# MIMXRT1011 register map
Vendor: nxp.com; File version: 1.0
CPU: CM7 r0p1, little endian, MPU, FPU, VTOR, 4 interrupt priority bits
Registers are 32-bit, read-write, reset 0x0 unless marked. A register's access mark holds for its fields unless they carry their own. Offsets are from the block's base; [hi:lo] are bit positions; 'fields as' and 'values as' point back to an identical list.

## TEMPMON — Temperature Monitor
Base 0x400D8000; register names take the prefix TEMPMON_; alternate view of CCM_ANALOG
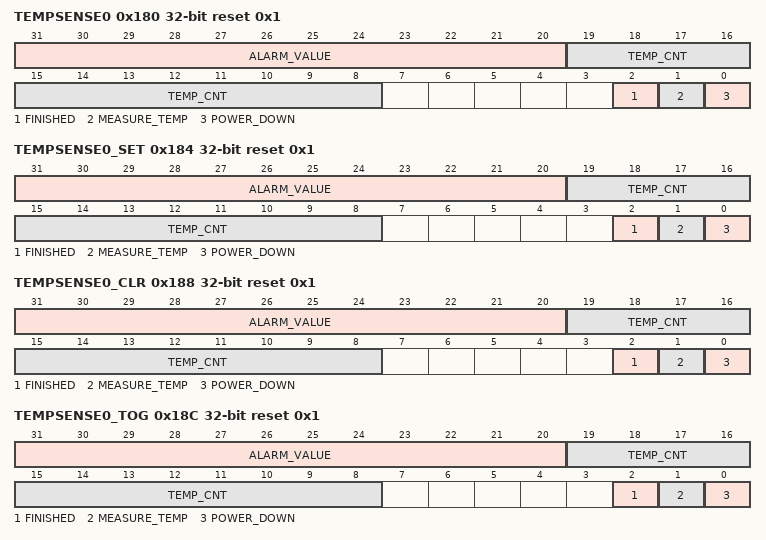
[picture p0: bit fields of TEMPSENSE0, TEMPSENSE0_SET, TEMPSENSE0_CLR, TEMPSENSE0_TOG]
0x180 TEMPSENSE0 reset 0x1 — Tempsensor Control Register 0
  [31:20] ALARM_VALUE — This bit field contains the temperature count (raw sensor output) that will generate a high alarm when TEMP_CNT is smaller than this field
  [19:8] TEMP_CNT ro — This bit field contains the last measured temperature count.
  [2] FINISHED ro — Indicates that the latest temp is valid
    0=INVALID (Last measurement is not ready yet.); 1=VALID (Last measurement is valid.)
  [1] MEASURE_TEMP — Starts the measurement process
    0=STOP (Do not start the measurement process.); 1=START (Start the measurement process.)
  [0] POWER_DOWN — This bit powers down the temperature sensor.
    0=POWER_UP (Enable power to the temperature sensor.); 1=POWER_DOWN (Power down the temperature sensor.)
0x184 TEMPSENSE0_SET reset 0x1 — Tempsensor Control Register 0
  fields as TEMPSENSE0
0x188 TEMPSENSE0_CLR reset 0x1 — Tempsensor Control Register 0
  fields as TEMPSENSE0
0x18C TEMPSENSE0_TOG reset 0x1 — Tempsensor Control Register 0
  fields as TEMPSENSE0
0x190 TEMPSENSE1 reset 0x1 — Tempsensor Control Register 1
  [15:0] MEASURE_FREQ — This bits determines how many RTC clocks to wait before automatically repeating a temperature measurement
0x194 TEMPSENSE1_SET reset 0x1 — Tempsensor Control Register 1
  fields as TEMPSENSE1
0x198 TEMPSENSE1_CLR reset 0x1 — Tempsensor Control Register 1
  fields as TEMPSENSE1
0x19C TEMPSENSE1_TOG reset 0x1 — Tempsensor Control Register 1
  fields as TEMPSENSE1
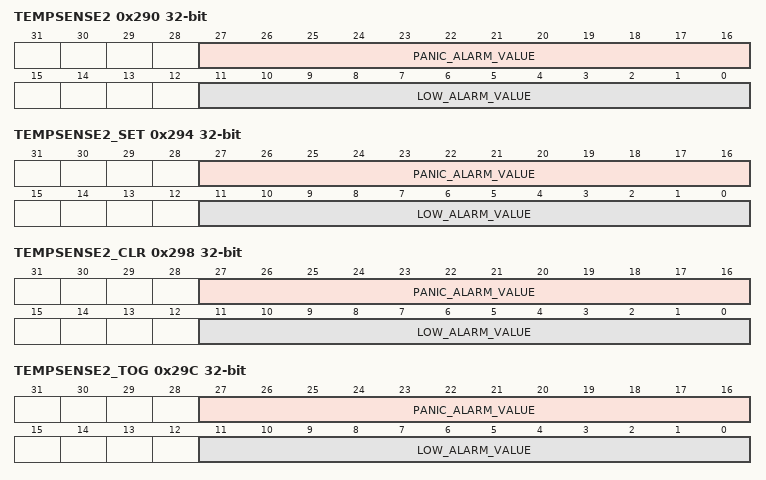
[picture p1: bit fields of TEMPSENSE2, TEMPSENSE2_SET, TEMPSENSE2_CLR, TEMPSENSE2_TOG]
0x290 TEMPSENSE2 — Tempsensor Control Register 2
  [27:16] PANIC_ALARM_VALUE — This bit field contains the temperature count that will generate a panic interrupt when TEMP_CNT is smaller than this field
  [11:0] LOW_ALARM_VALUE — This bit field contains the temperature count that will generate a low alarm interrupt when the field is exceeded by TEMP_CNT
0x294 TEMPSENSE2_SET — Tempsensor Control Register 2
  fields as TEMPSENSE2
0x298 TEMPSENSE2_CLR — Tempsensor Control Register 2
  fields as TEMPSENSE2
0x29C TEMPSENSE2_TOG — Tempsensor Control Register 2
  fields as TEMPSENSE2

## USBNC — USB
Base 0x400E4000; register names take the prefix USBNC_; alternate view of USB
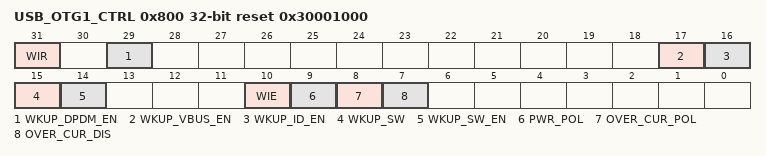
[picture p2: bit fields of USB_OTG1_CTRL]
0x800 USB_OTG1_CTRL reset 0x30001000 — USB OTG1 Control Register
  [31] WIR ro — OTG1 Wake-up Interrupt Request This bit indicates that a wake-up interrupt request is received on the OTG1 port
    0=No wake-up interrupt request received; 1=Wake-up Interrupt Request received
  [29] WKUP_DPDM_EN — Wake-up on DPDM change enable
    0=DPDM changes wake-up to be disabled only when VBUS is 0; 1=(Default) DPDM changes wake-up to be enabled, it is for device only
  [17] WKUP_VBUS_EN — OTG1 wake-up on VBUS change enable
    0=Disable; 1=Enable
  [16] WKUP_ID_EN — OTG1 Wake-up on ID change enable
    0=Disable; 1=Enable
  [15] WKUP_SW — OTG1 Software Wake-up
    0=Inactive; 1=Force wake-up
  [14] WKUP_SW_EN — OTG1 Software Wake-up Enable
    0=Disable; 1=Enable
  [10] WIE — OTG1 Wake-up Interrupt Enable This bit enables or disables the OTG1 wake-up interrupt
    0=Interrupt Disabled; 1=Interrupt Enabled
  [9] PWR_POL — OTG1 Power Polarity This bit should be set according to PMIC Power Pin polarity.
    0=PMIC Power Pin is Low active; 1=PMIC Power Pin is High active
  [8] OVER_CUR_POL — OTG1 Polarity of Overcurrent The polarity of OTG1 port overcurrent event
    0=High active (high on this signal represents an overcurrent condition); 1=Low active (low on this signal represents an overcurrent condition)
  [7] OVER_CUR_DIS — Disable OTG1 Overcurrent Detection
    0=Enables overcurrent detection; 1=Disables overcurrent detection
0x818 USB_OTG1_PHY_CTRL_0 — OTG1 UTMI PHY Control 0 Register
  [31] UTMI_CLK_VLD — Indicating whether OTG1 UTMI PHY clock is valid
    0=Invalid; 1=Valid
